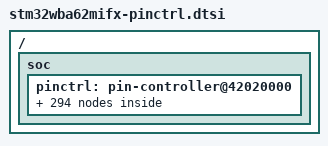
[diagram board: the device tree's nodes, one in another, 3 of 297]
/*
 * NOTE: Autogenerated file using genpinctrl.py
 *
 * SPDX-License-Identifier: Apache-2.0
 */

#include <zephyr/dt-bindings/pinctrl/stm32-pinctrl.h>

/ {
	soc {
		pinctrl: pin-controller@42020000 {

			/* ADC_IN / ADC_INN / ADC_INP */

			/omit-if-no-ref/ adc4_in9_pa0: adc4_in9_pa0 {
				pinmux = <STM32_PINMUX('A', 0, ANALOG)>;
			};

			/omit-if-no-ref/ adc4_in8_pa1: adc4_in8_pa1 {
				pinmux = <STM32_PINMUX('A', 1, ANALOG)>;
			};

			/omit-if-no-ref/ adc4_in7_pa2: adc4_in7_pa2 {
				pinmux = <STM32_PINMUX('A', 2, ANALOG)>;
			};

			/omit-if-no-ref/ adc4_in6_pa3: adc4_in6_pa3 {
				pinmux = <STM32_PINMUX('A', 3, ANALOG)>;
			};

			/omit-if-no-ref/ adc4_in5_pa4: adc4_in5_pa4 {
				pinmux = <STM32_PINMUX('A', 4, ANALOG)>;
			};

			/omit-if-no-ref/ adc4_in4_pa5: adc4_in4_pa5 {
				pinmux = <STM32_PINMUX('A', 5, ANALOG)>;
			};

			/omit-if-no-ref/ adc4_in3_pa6: adc4_in3_pa6 {
				pinmux = <STM32_PINMUX('A', 6, ANALOG)>;
			};

			/omit-if-no-ref/ adc4_in2_pa7: adc4_in2_pa7 {
				pinmux = <STM32_PINMUX('A', 7, ANALOG)>;
			};

			/omit-if-no-ref/ adc4_in1_pa8: adc4_in1_pa8 {
				pinmux = <STM32_PINMUX('A', 8, ANALOG)>;
			};

			/omit-if-no-ref/ adc4_in10_pb9: adc4_in10_pb9 {
				pinmux = <STM32_PINMUX('B', 9, ANALOG)>;
			};

			/* Analog */

			/omit-if-no-ref/ analog_pa0: analog_pa0 {
				pinmux = <STM32_PINMUX('A', 0, ANALOG)>;
			};

			/omit-if-no-ref/ analog_pa1: analog_pa1 {
				pinmux = <STM32_PINMUX('A', 1, ANALOG)>;
			};

			/omit-if-no-ref/ analog_pa2: analog_pa2 {
				pinmux = <STM32_PINMUX('A', 2, ANALOG)>;
			};

			/omit-if-no-ref/ analog_pa3: analog_pa3 {
				pinmux = <STM32_PINMUX('A', 3, ANALOG)>;
			};

			/omit-if-no-ref/ analog_pa4: analog_pa4 {
				pinmux = <STM32_PINMUX('A', 4, ANALOG)>;
			};

			/omit-if-no-ref/ analog_pa5: analog_pa5 {
				pinmux = <STM32_PINMUX('A', 5, ANALOG)>;
			};

			/omit-if-no-ref/ analog_pa6: analog_pa6 {
				pinmux = <STM32_PINMUX('A', 6, ANALOG)>;
			};

			/omit-if-no-ref/ analog_pa7: analog_pa7 {
				pinmux = <STM32_PINMUX('A', 7, ANALOG)>;
			};

			/omit-if-no-ref/ analog_pa8: analog_pa8 {
				pinmux = <STM32_PINMUX('A', 8, ANALOG)>;
			};

			/omit-if-no-ref/ analog_pa9: analog_pa9 {
				pinmux = <STM32_PINMUX('A', 9, ANALOG)>;
			};

			/omit-if-no-ref/ analog_pa10: analog_pa10 {
				pinmux = <STM32_PINMUX('A', 10, ANALOG)>;
			};

			/omit-if-no-ref/ analog_pa11: analog_pa11 {
				pinmux = <STM32_PINMUX('A', 11, ANALOG)>;
			};

			/omit-if-no-ref/ analog_pa12: analog_pa12 {
				pinmux = <STM32_PINMUX('A', 12, ANALOG)>;
			};

			/omit-if-no-ref/ analog_pa13: analog_pa13 {
				pinmux = <STM32_PINMUX('A', 13, ANALOG)>;
			};

			/omit-if-no-ref/ analog_pa14: analog_pa14 {
				pinmux = <STM32_PINMUX('A', 14, ANALOG)>;
			};

			/omit-if-no-ref/ analog_pa15: analog_pa15 {
				pinmux = <STM32_PINMUX('A', 15, ANALOG)>;
			};

			/omit-if-no-ref/ analog_pb0: analog_pb0 {
				pinmux = <STM32_PINMUX('B', 0, ANALOG)>;
			};

			/omit-if-no-ref/ analog_pb1: analog_pb1 {
				pinmux = <STM32_PINMUX('B', 1, ANALOG)>;
			};

			/omit-if-no-ref/ analog_pb2: analog_pb2 {
				pinmux = <STM32_PINMUX('B', 2, ANALOG)>;
			};

			/omit-if-no-ref/ analog_pb3: analog_pb3 {
				pinmux = <STM32_PINMUX('B', 3, ANALOG)>;
			};

			/omit-if-no-ref/ analog_pb4: analog_pb4 {
				pinmux = <STM32_PINMUX('B', 4, ANALOG)>;
			};

			/omit-if-no-ref/ analog_pb5: analog_pb5 {
				pinmux = <STM32_PINMUX('B', 5, ANALOG)>;
			};

			/omit-if-no-ref/ analog_pb6: analog_pb6 {
				pinmux = <STM32_PINMUX('B', 6, ANALOG)>;
			};

			/omit-if-no-ref/ analog_pb7: analog_pb7 {
				pinmux = <STM32_PINMUX('B', 7, ANALOG)>;
			};

			/omit-if-no-ref/ analog_pb8: analog_pb8 {
				pinmux = <STM32_PINMUX('B', 8, ANALOG)>;
			};

			/omit-if-no-ref/ analog_pb9: analog_pb9 {
				pinmux = <STM32_PINMUX('B', 9, ANALOG)>;
			};

			/omit-if-no-ref/ analog_pb10: analog_pb10 {
				pinmux = <STM32_PINMUX('B', 10, ANALOG)>;
			};

			/omit-if-no-ref/ analog_pb11: analog_pb11 {
				pinmux = <STM32_PINMUX('B', 11, ANALOG)>;
			};

			/omit-if-no-ref/ analog_pb12: analog_pb12 {
				pinmux = <STM32_PINMUX('B', 12, ANALOG)>;
			};

			/omit-if-no-ref/ analog_pb13: analog_pb13 {
				pinmux = <STM32_PINMUX('B', 13, ANALOG)>;
			};

			/omit-if-no-ref/ analog_pb14: analog_pb14 {
				pinmux = <STM32_PINMUX('B', 14, ANALOG)>;
			};

			/omit-if-no-ref/ analog_pb15: analog_pb15 {
				pinmux = <STM32_PINMUX('B', 15, ANALOG)>;
			};

			/omit-if-no-ref/ analog_pc0: analog_pc0 {
				pinmux = <STM32_PINMUX('C', 0, ANALOG)>;
			};

			/omit-if-no-ref/ analog_pc1: analog_pc1 {
				pinmux = <STM32_PINMUX('C', 1, ANALOG)>;
			};

			/omit-if-no-ref/ analog_pc3: analog_pc3 {
				pinmux = <STM32_PINMUX('C', 3, ANALOG)>;
			};

			/omit-if-no-ref/ analog_pc4: analog_pc4 {
				pinmux = <STM32_PINMUX('C', 4, ANALOG)>;
			};

			/omit-if-no-ref/ analog_pc5: analog_pc5 {
				pinmux = <STM32_PINMUX('C', 5, ANALOG)>;
			};

			/omit-if-no-ref/ analog_pc6: analog_pc6 {
				pinmux = <STM32_PINMUX('C', 6, ANALOG)>;
			};

			/omit-if-no-ref/ analog_pc7: analog_pc7 {
				pinmux = <STM32_PINMUX('C', 7, ANALOG)>;
			};

			/omit-if-no-ref/ analog_pc8: analog_pc8 {
				pinmux = <STM32_PINMUX('C', 8, ANALOG)>;
			};

			/omit-if-no-ref/ analog_pc13: analog_pc13 {
				pinmux = <STM32_PINMUX('C', 13, ANALOG)>;
			};

			/omit-if-no-ref/ analog_pc14: analog_pc14 {
				pinmux = <STM32_PINMUX('C', 14, ANALOG)>;
			};

			/omit-if-no-ref/ analog_pc15: analog_pc15 {
				pinmux = <STM32_PINMUX('C', 15, ANALOG)>;
			};

			/omit-if-no-ref/ analog_pd5: analog_pd5 {
				pinmux = <STM32_PINMUX('D', 5, ANALOG)>;
			};

			/omit-if-no-ref/ analog_pd6: analog_pd6 {
				pinmux = <STM32_PINMUX('D', 6, ANALOG)>;
			};

			/omit-if-no-ref/ analog_pd7: analog_pd7 {
				pinmux = <STM32_PINMUX('D', 7, ANALOG)>;
			};

			/omit-if-no-ref/ analog_pd8: analog_pd8 {
				pinmux = <STM32_PINMUX('D', 8, ANALOG)>;
			};

			/omit-if-no-ref/ analog_pd9: analog_pd9 {
				pinmux = <STM32_PINMUX('D', 9, ANALOG)>;
			};

			/omit-if-no-ref/ analog_pd14: analog_pd14 {
				pinmux = <STM32_PINMUX('D', 14, ANALOG)>;
			};

			/omit-if-no-ref/ analog_pe0: analog_pe0 {
				pinmux = <STM32_PINMUX('E', 0, ANALOG)>;
			};

			/omit-if-no-ref/ analog_pe1: analog_pe1 {
				pinmux = <STM32_PINMUX('E', 1, ANALOG)>;
			};

			/omit-if-no-ref/ analog_pe2: analog_pe2 {
				pinmux = <STM32_PINMUX('E', 2, ANALOG)>;
			};

			/omit-if-no-ref/ analog_pe3: analog_pe3 {
				pinmux = <STM32_PINMUX('E', 3, ANALOG)>;
			};

			/omit-if-no-ref/ analog_ph3: analog_ph3 {
				pinmux = <STM32_PINMUX('H', 3, ANALOG)>;
			};

			/* COMP_IN */

			/omit-if-no-ref/ comp1_inm_pa1: comp1_inm_pa1 {
				pinmux = <STM32_PINMUX('A', 1, ANALOG)>;
			};

			/omit-if-no-ref/ comp1_inp_pa2: comp1_inp_pa2 {
				pinmux = <STM32_PINMUX('A', 2, ANALOG)>;
			};

			/omit-if-no-ref/ comp2_inp_pa0: comp2_inp_pa0 {
				pinmux = <STM32_PINMUX('A', 0, ANALOG)>;
			};

			/omit-if-no-ref/ comp2_inm_pb9: comp2_inm_pb9 {
				pinmux = <STM32_PINMUX('B', 9, ANALOG)>;
			};

			/* COMP_OUT */

			/omit-if-no-ref/ comp1_out_pa7: comp1_out_pa7 {
				pinmux = <STM32_PINMUX('A', 7, AF12)>;
			};

			/omit-if-no-ref/ comp1_out_pb8: comp1_out_pb8 {
				pinmux = <STM32_PINMUX('B', 8, AF12)>;
			};

			/omit-if-no-ref/ comp2_out_pa12: comp2_out_pa12 {
				pinmux = <STM32_PINMUX('A', 12, AF12)>;
			};

			/omit-if-no-ref/ comp2_out_pa14: comp2_out_pa14 {
				pinmux = <STM32_PINMUX('A', 14, AF12)>;
			};

			/* I2C_SCL */

			/omit-if-no-ref/ i2c1_scl_pa15: i2c1_scl_pa15 {
				pinmux = <STM32_PINMUX('A', 15, AF4)>;
				bias-pull-up;
				drive-open-drain;
			};

			/omit-if-no-ref/ i2c1_scl_pb2: i2c1_scl_pb2 {
				pinmux = <STM32_PINMUX('B', 2, AF4)>;
				bias-pull-up;
				drive-open-drain;
			};

			/omit-if-no-ref/ i2c2_scl_pb10: i2c2_scl_pb10 {
				pinmux = <STM32_PINMUX('B', 10, AF4)>;
				bias-pull-up;
				drive-open-drain;
			};

			/omit-if-no-ref/ i2c2_scl_pb13: i2c2_scl_pb13 {
				pinmux = <STM32_PINMUX('B', 13, AF4)>;
				bias-pull-up;
				drive-open-drain;
			};

			/omit-if-no-ref/ i2c3_scl_pa6: i2c3_scl_pa6 {
				pinmux = <STM32_PINMUX('A', 6, AF4)>;
				bias-pull-up;
				drive-open-drain;
			};

			/omit-if-no-ref/ i2c3_scl_pb2: i2c3_scl_pb2 {
				pinmux = <STM32_PINMUX('B', 2, AF6)>;
				bias-pull-up;
				drive-open-drain;
			};

			/omit-if-no-ref/ i2c3_scl_pc0: i2c3_scl_pc0 {
				pinmux = <STM32_PINMUX('C', 0, AF4)>;
				bias-pull-up;
				drive-open-drain;
			};

			/omit-if-no-ref/ i2c4_scl_pb10: i2c4_scl_pb10 {
				pinmux = <STM32_PINMUX('B', 10, AF3)>;
				bias-pull-up;
				drive-open-drain;
			};

			/* I2C_SDA */

			/omit-if-no-ref/ i2c1_sda_pb1: i2c1_sda_pb1 {
				pinmux = <STM32_PINMUX('B', 1, AF4)>;
				bias-pull-up;
				drive-open-drain;
			};

			/omit-if-no-ref/ i2c1_sda_pb3: i2c1_sda_pb3 {
				pinmux = <STM32_PINMUX('B', 3, AF4)>;
				bias-pull-up;
				drive-open-drain;
			};

			/omit-if-no-ref/ i2c2_sda_pb11: i2c2_sda_pb11 {
				pinmux = <STM32_PINMUX('B', 11, AF4)>;
				bias-pull-up;
				drive-open-drain;
			};

			/omit-if-no-ref/ i2c2_sda_pb14: i2c2_sda_pb14 {
				pinmux = <STM32_PINMUX('B', 14, AF4)>;
				bias-pull-up;
				drive-open-drain;
			};

			/omit-if-no-ref/ i2c3_sda_pa7: i2c3_sda_pa7 {
				pinmux = <STM32_PINMUX('A', 7, AF4)>;
				bias-pull-up;
				drive-open-drain;
			};

			/omit-if-no-ref/ i2c3_sda_pb1: i2c3_sda_pb1 {
				pinmux = <STM32_PINMUX('B', 1, AF6)>;
				bias-pull-up;
				drive-open-drain;
			};

			/omit-if-no-ref/ i2c3_sda_pc1: i2c3_sda_pc1 {
				pinmux = <STM32_PINMUX('C', 1, AF4)>;
				bias-pull-up;
				drive-open-drain;
			};

			/omit-if-no-ref/ i2c4_sda_pb11: i2c4_sda_pb11 {
				pinmux = <STM32_PINMUX('B', 11, AF3)>;
				bias-pull-up;
				drive-open-drain;
			};

			/* I2C_SMBA */

			/omit-if-no-ref/ i2c1_smba_pb15: i2c1_smba_pb15 {
				pinmux = <STM32_PINMUX('B', 15, AF4)>;
				bias-pull-up;
			};

			/omit-if-no-ref/ i2c2_smba_pb12: i2c2_smba_pb12 {
				pinmux = <STM32_PINMUX('B', 12, AF4)>;
				bias-pull-up;
			};

			/omit-if-no-ref/ i2c3_smba_pb15: i2c3_smba_pb15 {
				pinmux = <STM32_PINMUX('B', 15, AF6)>;
				bias-pull-up;
			};

			/omit-if-no-ref/ i2c4_smba_pa14: i2c4_smba_pa14 {
				pinmux = <STM32_PINMUX('A', 14, AF5)>;
				bias-pull-up;
			};

			/* JTAG PORT */

			/omit-if-no-ref/ debug_jtms_swdio_pa13: debug_jtms_swdio_pa13 {
				pinmux = <STM32_PINMUX('A', 13, AF0)>;
			};

			/omit-if-no-ref/ debug_jtck_swclk_pa14: debug_jtck_swclk_pa14 {
				pinmux = <STM32_PINMUX('A', 14, AF0)>;
			};

			/omit-if-no-ref/ debug_jtdi_pa15: debug_jtdi_pa15 {
				pinmux = <STM32_PINMUX('A', 15, AF0)>;
			};

			/omit-if-no-ref/ debug_jtdo_swo_pb3: debug_jtdo_swo_pb3 {
				pinmux = <STM32_PINMUX('B', 3, AF0)>;
			};

			/omit-if-no-ref/ debug_njtrst_pb4: debug_njtrst_pb4 {
				pinmux = <STM32_PINMUX('B', 4, AF0)>;
			};

			/* RCC_MCO */

			/omit-if-no-ref/ rcc_mco_pa8: rcc_mco_pa8 {
				pinmux = <STM32_PINMUX('A', 8, AF0)>;
				slew-rate = "very-high-speed";
			};

			/* SAI */

			/omit-if-no-ref/ sai1_ck1_pa1: sai1_ck1_pa1 {
				pinmux = <STM32_PINMUX('A', 1, AF3)>;
			};

			/omit-if-no-ref/ sai1_d1_pa2: sai1_d1_pa2 {
				pinmux = <STM32_PINMUX('A', 2, AF3)>;
			};

			/omit-if-no-ref/ sai1_d2_pa5: sai1_d2_pa5 {
				pinmux = <STM32_PINMUX('A', 5, AF3)>;
			};

			/omit-if-no-ref/ sai1_ck2_pa6: sai1_ck2_pa6 {
				pinmux = <STM32_PINMUX('A', 6, AF3)>;
			};

			/omit-if-no-ref/ sai1_mclk_a_pa6: sai1_mclk_a_pa6 {
				pinmux = <STM32_PINMUX('A', 6, AF13)>;
			};

			/omit-if-no-ref/ sai1_sck_a_pa7: sai1_sck_a_pa7 {
				pinmux = <STM32_PINMUX('A', 7, AF13)>;
			};

			/omit-if-no-ref/ sai1_fs_a_pa8: sai1_fs_a_pa8 {
				pinmux = <STM32_PINMUX('A', 8, AF13)>;
			};

			/omit-if-no-ref/ sai1_ck1_pa9: sai1_ck1_pa9 {
				pinmux = <STM32_PINMUX('A', 9, AF3)>;
			};

			/omit-if-no-ref/ sai1_d1_pa10: sai1_d1_pa10 {
				pinmux = <STM32_PINMUX('A', 10, AF3)>;
			};

			/omit-if-no-ref/ sai1_mclk_b_pb4: sai1_mclk_b_pb4 {
				pinmux = <STM32_PINMUX('B', 4, AF13)>;
			};

			/omit-if-no-ref/ sai1_d2_pb5: sai1_d2_pb5 {
				pinmux = <STM32_PINMUX('B', 5, AF3)>;
			};

			/omit-if-no-ref/ sai1_fs_b_pb5: sai1_fs_b_pb5 {
				pinmux = <STM32_PINMUX('B', 5, AF13)>;
			};

			/omit-if-no-ref/ sai1_sck_b_pb6: sai1_sck_b_pb6 {
				pinmux = <STM32_PINMUX('B', 6, AF13)>;
			};

			/omit-if-no-ref/ sai1_sd_b_pb7: sai1_sd_b_pb7 {
				pinmux = <STM32_PINMUX('B', 7, AF13)>;
			};

			/omit-if-no-ref/ sai1_sd_a_pb12: sai1_sd_a_pb12 {
				pinmux = <STM32_PINMUX('B', 12, AF13)>;
			};

			/omit-if-no-ref/ sai1_sd_a_pb14: sai1_sd_a_pb14 {
				pinmux = <STM32_PINMUX('B', 14, AF13)>;
			};

			/omit-if-no-ref/ sai1_sd_a_pc1: sai1_sd_a_pc1 {
				pinmux = <STM32_PINMUX('C', 1, AF13)>;
			};

			/omit-if-no-ref/ sai1_d1_pc3: sai1_d1_pc3 {
				pinmux = <STM32_PINMUX('C', 3, AF3)>;
			};

			/omit-if-no-ref/ sai1_sd_a_pc3: sai1_sd_a_pc3 {
				pinmux = <STM32_PINMUX('C', 3, AF13)>;
			};

			/omit-if-no-ref/ sai1_d2_pc4: sai1_d2_pc4 {
				pinmux = <STM32_PINMUX('C', 4, AF3)>;
			};

			/omit-if-no-ref/ sai1_fs_a_pc4: sai1_fs_a_pc4 {
				pinmux = <STM32_PINMUX('C', 4, AF13)>;
			};

			/omit-if-no-ref/ sai1_d3_pc5: sai1_d3_pc5 {
				pinmux = <STM32_PINMUX('C', 5, AF3)>;
			};

			/omit-if-no-ref/ sai1_sd_b_pc5: sai1_sd_b_pc5 {
				pinmux = <STM32_PINMUX('C', 5, AF13)>;
			};

			/omit-if-no-ref/ sai1_d1_pd5: sai1_d1_pd5 {
				pinmux = <STM32_PINMUX('D', 5, AF3)>;
			};

			/omit-if-no-ref/ sai1_sd_a_pd5: sai1_sd_a_pd5 {
				pinmux = <STM32_PINMUX('D', 5, AF13)>;
			};

			/omit-if-no-ref/ sai1_ck1_pe2: sai1_ck1_pe2 {
				pinmux = <STM32_PINMUX('E', 2, AF3)>;
			};

			/omit-if-no-ref/ sai1_mclk_a_pe2: sai1_mclk_a_pe2 {
				pinmux = <STM32_PINMUX('E', 2, AF13)>;
			};

			/omit-if-no-ref/ sai1_sd_b_pe3: sai1_sd_b_pe3 {
				pinmux = <STM32_PINMUX('E', 3, AF13)>;
			};

			/* SPI_MISO */

			/omit-if-no-ref/ spi1_miso_pb3: spi1_miso_pb3 {
				pinmux = <STM32_PINMUX('B', 3, AF5)>;
				bias-pull-down;
			};

			/omit-if-no-ref/ spi2_miso_pa9: spi2_miso_pa9 {
				pinmux = <STM32_PINMUX('A', 9, AF5)>;
				bias-pull-down;
			};

			/omit-if-no-ref/ spi2_miso_pb14: spi2_miso_pb14 {
				pinmux = <STM32_PINMUX('B', 14, AF5)>;
				bias-pull-down;
			};

			/omit-if-no-ref/ spi3_miso_pa1: spi3_miso_pa1 {
				pinmux = <STM32_PINMUX('A', 1, AF6)>;
				bias-pull-down;
			};

			/omit-if-no-ref/ spi3_miso_pb9: spi3_miso_pb9 {
				pinmux = <STM32_PINMUX('B', 9, AF6)>;
				bias-pull-down;
			};

			/omit-if-no-ref/ spi3_miso_pc4: spi3_miso_pc4 {
				pinmux = <STM32_PINMUX('C', 4, AF6)>;
				bias-pull-down;
			};

			/* SPI_MOSI */

			/omit-if-no-ref/ spi1_mosi_pa15: spi1_mosi_pa15 {
				pinmux = <STM32_PINMUX('A', 15, AF5)>;
				bias-pull-down;
			};

			/omit-if-no-ref/ spi2_mosi_pb0: spi2_mosi_pb0 {
				pinmux = <STM32_PINMUX('B', 0, AF5)>;
				bias-pull-down;
			};

			/omit-if-no-ref/ spi2_mosi_pc1: spi2_mosi_pc1 {
				pinmux = <STM32_PINMUX('C', 1, AF3)>;
				bias-pull-down;
			};

			/omit-if-no-ref/ spi2_mosi_pc3: spi2_mosi_pc3 {
				pinmux = <STM32_PINMUX('C', 3, AF5)>;
				bias-pull-down;
			};

			/omit-if-no-ref/ spi3_mosi_pb8: spi3_mosi_pb8 {
				pinmux = <STM32_PINMUX('B', 8, AF6)>;
				bias-pull-down;
			};

			/omit-if-no-ref/ spi3_mosi_pc3: spi3_mosi_pc3 {
				pinmux = <STM32_PINMUX('C', 3, AF6)>;
				bias-pull-down;
			};

			/omit-if-no-ref/ spi3_mosi_pd5: spi3_mosi_pd5 {
				pinmux = <STM32_PINMUX('D', 5, AF5)>;
				bias-pull-down;
			};

			/* SPI_NSS */

			/omit-if-no-ref/ spi1_nss_pa12: spi1_nss_pa12 {
				pinmux = <STM32_PINMUX('A', 12, AF5)>;
				bias-pull-up;
			};

			/omit-if-no-ref/ spi2_nss_pa10: spi2_nss_pa10 {
				pinmux = <STM32_PINMUX('A', 10, AF6)>;
				bias-pull-up;
			};

			/omit-if-no-ref/ spi2_nss_pb9: spi2_nss_pb9 {
				pinmux = <STM32_PINMUX('B', 9, AF5)>;
				bias-pull-up;
			};

			/omit-if-no-ref/ spi2_nss_pb12: spi2_nss_pb12 {
				pinmux = <STM32_PINMUX('B', 12, AF6)>;
				bias-pull-up;
			};

			/omit-if-no-ref/ spi3_nss_pa5: spi3_nss_pa5 {
				pinmux = <STM32_PINMUX('A', 5, AF6)>;
				bias-pull-up;
			};

			/* SPI_SCK */

			/omit-if-no-ref/ spi1_sck_pb4: spi1_sck_pb4 {
				pinmux = <STM32_PINMUX('B', 4, AF5)>;
				bias-pull-down;
				slew-rate = "very-high-speed";
			};

			/omit-if-no-ref/ spi2_sck_pa9: spi2_sck_pa9 {
				pinmux = <STM32_PINMUX('A', 9, AF6)>;
				bias-pull-down;
				slew-rate = "very-high-speed";
			};

			/omit-if-no-ref/ spi2_sck_pb10: spi2_sck_pb10 {
				pinmux = <STM32_PINMUX('B', 10, AF5)>;
				bias-pull-down;
				slew-rate = "very-high-speed";
			};

			/omit-if-no-ref/ spi2_sck_pb13: spi2_sck_pb13 {
				pinmux = <STM32_PINMUX('B', 13, AF5)>;
				bias-pull-down;
				slew-rate = "very-high-speed";
			};

			/omit-if-no-ref/ spi3_sck_pa0: spi3_sck_pa0 {
				pinmux = <STM32_PINMUX('A', 0, AF6)>;
				bias-pull-down;
				slew-rate = "very-high-speed";
			};

			/omit-if-no-ref/ spi3_sck_pa7: spi3_sck_pa7 {
				pinmux = <STM32_PINMUX('A', 7, AF6)>;
				bias-pull-down;
				slew-rate = "very-high-speed";
			};

			/* TIM_BKIN */

			/omit-if-no-ref/ tim1_bkin_pa2: tim1_bkin_pa2 {
				pinmux = <STM32_PINMUX('A', 2, AF1)>;
			};

			/omit-if-no-ref/ tim1_bkin2_pb15: tim1_bkin2_pb15 {
				pinmux = <STM32_PINMUX('B', 15, AF1)>;
			};

			/omit-if-no-ref/ tim1_bkin2_pc13: tim1_bkin2_pc13 {
				pinmux = <STM32_PINMUX('C', 13, AF2)>;
			};

			/omit-if-no-ref/ tim16_bkin_pb10: tim16_bkin_pb10 {
				pinmux = <STM32_PINMUX('B', 10, AF14)>;
			};

			/omit-if-no-ref/ tim16_bkin_pb15: tim16_bkin_pb15 {
				pinmux = <STM32_PINMUX('B', 15, AF14)>;
			};

			/omit-if-no-ref/ tim17_bkin_pa15: tim17_bkin_pa15 {
				pinmux = <STM32_PINMUX('A', 15, AF14)>;
			};

			/* TIM_CH / TIM_CHN */

			/omit-if-no-ref/ tim1_ch2n_pa0: tim1_ch2n_pa0 {
				pinmux = <STM32_PINMUX('A', 0, AF1)>;
			};

			/omit-if-no-ref/ tim1_ch1n_pa1: tim1_ch1n_pa1 {
				pinmux = <STM32_PINMUX('A', 1, AF1)>;
			};

			/omit-if-no-ref/ tim1_ch1_pa11: tim1_ch1_pa11 {
				pinmux = <STM32_PINMUX('A', 11, AF1)>;
			};

			/omit-if-no-ref/ tim1_ch2_pa12: tim1_ch2_pa12 {
				pinmux = <STM32_PINMUX('A', 12, AF1)>;
			};

			/omit-if-no-ref/ tim1_ch3n_pb0: tim1_ch3n_pb0 {
				pinmux = <STM32_PINMUX('B', 0, AF1)>;
			};

			/omit-if-no-ref/ tim1_ch2n_pb1: tim1_ch2n_pb1 {
				pinmux = <STM32_PINMUX('B', 1, AF1)>;
			};

			/omit-if-no-ref/ tim1_ch1n_pb2: tim1_ch1n_pb2 {
				pinmux = <STM32_PINMUX('B', 2, AF1)>;
			};

			/omit-if-no-ref/ tim1_ch4_pb3: tim1_ch4_pb3 {
				pinmux = <STM32_PINMUX('B', 3, AF1)>;
			};

			/omit-if-no-ref/ tim1_ch3_pb4: tim1_ch3_pb4 {
				pinmux = <STM32_PINMUX('B', 4, AF1)>;
			};

			/omit-if-no-ref/ tim1_ch4n_pb7: tim1_ch4n_pb7 {
				pinmux = <STM32_PINMUX('B', 7, AF1)>;
			};

			/omit-if-no-ref/ tim1_ch1_pb8: tim1_ch1_pb8 {
				pinmux = <STM32_PINMUX('B', 8, AF1)>;
			};

			/omit-if-no-ref/ tim1_ch3n_pb9: tim1_ch3n_pb9 {
				pinmux = <STM32_PINMUX('B', 9, AF1)>;
			};

			/omit-if-no-ref/ tim1_ch4n_pc5: tim1_ch4n_pc5 {
				pinmux = <STM32_PINMUX('C', 5, AF1)>;
			};

			/omit-if-no-ref/ tim2_ch1_pa5: tim2_ch1_pa5 {
				pinmux = <STM32_PINMUX('A', 5, AF1)>;
			};

			/omit-if-no-ref/ tim2_ch4_pa6: tim2_ch4_pa6 {
				pinmux = <STM32_PINMUX('A', 6, AF1)>;
			};

			/omit-if-no-ref/ tim2_ch3_pa7: tim2_ch3_pa7 {
				pinmux = <STM32_PINMUX('A', 7, AF1)>;
			};

			/omit-if-no-ref/ tim2_ch2_pa8: tim2_ch2_pa8 {
				pinmux = <STM32_PINMUX('A', 8, AF1)>;
			};

			/omit-if-no-ref/ tim2_ch1_pb6: tim2_ch1_pb6 {
				pinmux = <STM32_PINMUX('B', 6, AF1)>;
			};

			/omit-if-no-ref/ tim2_ch1_pb12: tim2_ch1_pb12 {
				pinmux = <STM32_PINMUX('B', 12, AF1)>;
			};

			/omit-if-no-ref/ tim3_ch3_pa0: tim3_ch3_pa0 {
				pinmux = <STM32_PINMUX('A', 0, AF2)>;
			};

			/omit-if-no-ref/ tim3_ch2_pa1: tim3_ch2_pa1 {
				pinmux = <STM32_PINMUX('A', 1, AF2)>;
			};

			/omit-if-no-ref/ tim3_ch1_pa2: tim3_ch1_pa2 {
				pinmux = <STM32_PINMUX('A', 2, AF2)>;
			};

			/omit-if-no-ref/ tim3_ch2_pa9: tim3_ch2_pa9 {
				pinmux = <STM32_PINMUX('A', 9, AF2)>;
			};

			/omit-if-no-ref/ tim3_ch1_pa10: tim3_ch1_pa10 {
				pinmux = <STM32_PINMUX('A', 10, AF2)>;
			};

			/omit-if-no-ref/ tim3_ch1_pb5: tim3_ch1_pb5 {
				pinmux = <STM32_PINMUX('B', 5, AF2)>;
			};

			/omit-if-no-ref/ tim3_ch4_pb9: tim3_ch4_pb9 {
				pinmux = <STM32_PINMUX('B', 9, AF2)>;
			};

			/omit-if-no-ref/ tim3_ch4_pb13: tim3_ch4_pb13 {
				pinmux = <STM32_PINMUX('B', 13, AF2)>;
			};

			/omit-if-no-ref/ tim3_ch3_pb14: tim3_ch3_pb14 {
				pinmux = <STM32_PINMUX('B', 14, AF2)>;
			};

			/omit-if-no-ref/ tim3_ch1_pc3: tim3_ch1_pc3 {
				pinmux = <STM32_PINMUX('C', 3, AF2)>;
			};

			/omit-if-no-ref/ tim3_ch2_pc4: tim3_ch2_pc4 {
				pinmux = <STM32_PINMUX('C', 4, AF2)>;
			};

			/omit-if-no-ref/ tim3_ch1_pc6: tim3_ch1_pc6 {
				pinmux = <STM32_PINMUX('C', 6, AF2)>;
			};

			/omit-if-no-ref/ tim3_ch2_pc7: tim3_ch2_pc7 {
				pinmux = <STM32_PINMUX('C', 7, AF2)>;
			};

			/omit-if-no-ref/ tim3_ch3_pc8: tim3_ch3_pc8 {
				pinmux = <STM32_PINMUX('C', 8, AF2)>;
			};

			/omit-if-no-ref/ tim3_ch1_pe3: tim3_ch1_pe3 {
				pinmux = <STM32_PINMUX('E', 3, AF2)>;
			};

			/omit-if-no-ref/ tim4_ch1_pb6: tim4_ch1_pb6 {
				pinmux = <STM32_PINMUX('B', 6, AF12)>;
			};

			/omit-if-no-ref/ tim4_ch2_pb7: tim4_ch2_pb7 {
				pinmux = <STM32_PINMUX('B', 7, AF12)>;
			};

			/omit-if-no-ref/ tim4_ch3_pb8: tim4_ch3_pb8 {
				pinmux = <STM32_PINMUX('B', 8, AF13)>;
			};

			/omit-if-no-ref/ tim4_ch4_pb9: tim4_ch4_pb9 {
				pinmux = <STM32_PINMUX('B', 9, AF12)>;
			};

			/omit-if-no-ref/ tim4_ch3_pd14: tim4_ch3_pd14 {
				pinmux = <STM32_PINMUX('D', 14, AF13)>;
			};

			/omit-if-no-ref/ tim16_ch1_pa2: tim16_ch1_pa2 {
				pinmux = <STM32_PINMUX('A', 2, AF14)>;
			};

			/omit-if-no-ref/ tim16_ch1n_pa3: tim16_ch1n_pa3 {
				pinmux = <STM32_PINMUX('A', 3, AF14)>;
			};

			/omit-if-no-ref/ tim16_ch1_pa4: tim16_ch1_pa4 {
				pinmux = <STM32_PINMUX('A', 4, AF14)>;
			};

			/omit-if-no-ref/ tim16_ch1n_pb8: tim16_ch1n_pb8 {
				pinmux = <STM32_PINMUX('B', 8, AF14)>;
			};

			/omit-if-no-ref/ tim16_ch1_pb9: tim16_ch1_pb9 {
				pinmux = <STM32_PINMUX('B', 9, AF14)>;
			};

			/omit-if-no-ref/ tim16_ch1_pe0: tim16_ch1_pe0 {
				pinmux = <STM32_PINMUX('E', 0, AF14)>;
			};

			/omit-if-no-ref/ tim17_ch1_pa1: tim17_ch1_pa1 {
				pinmux = <STM32_PINMUX('A', 1, AF14)>;
			};

			/omit-if-no-ref/ tim17_ch1n_pb3: tim17_ch1n_pb3 {
				pinmux = <STM32_PINMUX('B', 3, AF14)>;
			};

			/omit-if-no-ref/ tim17_ch1_pb4: tim17_ch1_pb4 {
				pinmux = <STM32_PINMUX('B', 4, AF14)>;
			};

			/omit-if-no-ref/ tim17_ch1_pe1: tim17_ch1_pe1 {
				pinmux = <STM32_PINMUX('E', 1, AF14)>;
			};

			/* TSC */

			/omit-if-no-ref/ tsc_g2_io2_pa0: tsc_g2_io2_pa0 {
				pinmux = <STM32_PINMUX('A', 0, AF9)>;
			};

			/omit-if-no-ref/ tsc_g2_io1_pa1: tsc_g2_io1_pa1 {
				pinmux = <STM32_PINMUX('A', 1, AF9)>;
			};

			/omit-if-no-ref/ tsc_g4_io4_pa2: tsc_g4_io4_pa2 {
				pinmux = <STM32_PINMUX('A', 2, AF9)>;
			};

			/omit-if-no-ref/ tsc_g4_io2_pa3: tsc_g4_io2_pa3 {
				pinmux = <STM32_PINMUX('A', 3, AF9)>;
			};

			/omit-if-no-ref/ tsc_g4_io1_pa4: tsc_g4_io1_pa4 {
				pinmux = <STM32_PINMUX('A', 4, AF9)>;
			};

			/omit-if-no-ref/ tsc_g1_io4_pa5: tsc_g1_io4_pa5 {
				pinmux = <STM32_PINMUX('A', 5, AF9)>;
			};

			/omit-if-no-ref/ tsc_g1_io3_pa6: tsc_g1_io3_pa6 {
				pinmux = <STM32_PINMUX('A', 6, AF9)>;
			};

			/omit-if-no-ref/ tsc_g1_io2_pa7: tsc_g1_io2_pa7 {
				pinmux = <STM32_PINMUX('A', 7, AF9)>;
			};

			/omit-if-no-ref/ tsc_g1_io1_pa8: tsc_g1_io1_pa8 {
				pinmux = <STM32_PINMUX('A', 8, AF9)>;
			};

			/omit-if-no-ref/ tsc_g3_io4_pa12: tsc_g3_io4_pa12 {
				pinmux = <STM32_PINMUX('A', 12, AF9)>;
			};

			/omit-if-no-ref/ tsc_g3_io3_pa15: tsc_g3_io3_pa15 {
				pinmux = <STM32_PINMUX('A', 15, AF9)>;
			};

			/omit-if-no-ref/ tsc_g3_io2_pb3: tsc_g3_io2_pb3 {
				pinmux = <STM32_PINMUX('B', 3, AF9)>;
			};

			/omit-if-no-ref/ tsc_g3_io1_pb4: tsc_g3_io1_pb4 {
				pinmux = <STM32_PINMUX('B', 4, AF9)>;
			};

			/omit-if-no-ref/ tsc_g5_io4_pb5: tsc_g5_io4_pb5 {
				pinmux = <STM32_PINMUX('B', 5, AF9)>;
			};

			/omit-if-no-ref/ tsc_g5_io3_pb6: tsc_g5_io3_pb6 {
				pinmux = <STM32_PINMUX('B', 6, AF9)>;
			};

			/omit-if-no-ref/ tsc_g5_io2_pb7: tsc_g5_io2_pb7 {
				pinmux = <STM32_PINMUX('B', 7, AF9)>;
			};

			/omit-if-no-ref/ tsc_g2_io4_pb8: tsc_g2_io4_pb8 {
				pinmux = <STM32_PINMUX('B', 8, AF9)>;
			};

			/omit-if-no-ref/ tsc_g2_io3_pb9: tsc_g2_io3_pb9 {
				pinmux = <STM32_PINMUX('B', 9, AF9)>;
			};

			/omit-if-no-ref/ tsc_g4_io3_pb10: tsc_g4_io3_pb10 {
				pinmux = <STM32_PINMUX('B', 10, AF9)>;
			};

			/omit-if-no-ref/ tsc_sync_pb12: tsc_sync_pb12 {
				pinmux = <STM32_PINMUX('B', 12, AF9)>;
			};

			/omit-if-no-ref/ tsc_g6_io2_pb13: tsc_g6_io2_pb13 {
				pinmux = <STM32_PINMUX('B', 13, AF9)>;
			};

			/omit-if-no-ref/ tsc_g6_io1_pb14: tsc_g6_io1_pb14 {
				pinmux = <STM32_PINMUX('B', 14, AF9)>;
			};

			/omit-if-no-ref/ tsc_g5_io1_pc13: tsc_g5_io1_pc13 {
				pinmux = <STM32_PINMUX('C', 13, AF9)>;
			};

			/omit-if-no-ref/ tsc_g7_io4_pe0: tsc_g7_io4_pe0 {
				pinmux = <STM32_PINMUX('E', 0, AF9)>;
			};

			/omit-if-no-ref/ tsc_g7_io3_pe1: tsc_g7_io3_pe1 {
				pinmux = <STM32_PINMUX('E', 1, AF9)>;
			};

			/omit-if-no-ref/ tsc_g7_io2_pe2: tsc_g7_io2_pe2 {
				pinmux = <STM32_PINMUX('E', 2, AF9)>;
			};

			/omit-if-no-ref/ tsc_g7_io1_pe3: tsc_g7_io1_pe3 {
				pinmux = <STM32_PINMUX('E', 3, AF9)>;
			};

			/* UART_CTS / USART_CTS / LPUART_CTS */

			/omit-if-no-ref/ lpuart1_cts_pa0: lpuart1_cts_pa0 {
				pinmux = <STM32_PINMUX('A', 0, AF8)>;
				bias-pull-up;
			};

			/omit-if-no-ref/ usart1_cts_pa4: usart1_cts_pa4 {
				pinmux = <STM32_PINMUX('A', 4, AF7)>;
				bias-pull-up;
			};

			/omit-if-no-ref/ usart1_cts_pa7: usart1_cts_pa7 {
				pinmux = <STM32_PINMUX('A', 7, AF7)>;
				bias-pull-up;
			};

			/omit-if-no-ref/ lpuart1_cts_pb15: lpuart1_cts_pb15 {
				pinmux = <STM32_PINMUX('B', 15, AF8)>;
				bias-pull-up;
			};

			/omit-if-no-ref/ usart2_cts_pb2: usart2_cts_pb2 {
				pinmux = <STM32_PINMUX('B', 2, AF3)>;
				bias-pull-up;
			};

			/omit-if-no-ref/ usart2_cts_pb15: usart2_cts_pb15 {
				pinmux = <STM32_PINMUX('B', 15, AF3)>;
				bias-pull-up;
			};

			/omit-if-no-ref/ usart3_cts_pa6: usart3_cts_pa6 {
				pinmux = <STM32_PINMUX('A', 6, AF8)>;
				bias-pull-up;
			};

			/omit-if-no-ref/ usart3_cts_pb13: usart3_cts_pb13 {
				pinmux = <STM32_PINMUX('B', 13, AF7)>;
				bias-pull-up;
			};

			/* UART_DE / USART_DE / LPUART_DE */

			/omit-if-no-ref/ usart1_de_pa2: usart1_de_pa2 {
				pinmux = <STM32_PINMUX('A', 2, AF7)>;
				drive-push-pull;
			};

			/omit-if-no-ref/ usart1_de_pa3: usart1_de_pa3 {
				pinmux = <STM32_PINMUX('A', 3, AF7)>;
				drive-push-pull;
			};

			/omit-if-no-ref/ usart1_de_pa6: usart1_de_pa6 {
				pinmux = <STM32_PINMUX('A', 6, AF7)>;
				drive-push-pull;
			};

			/omit-if-no-ref/ lpuart1_de_pa9: lpuart1_de_pa9 {
				pinmux = <STM32_PINMUX('A', 9, AF8)>;
				drive-push-pull;
			};

			/omit-if-no-ref/ lpuart1_de_pb9: lpuart1_de_pb9 {
				pinmux = <STM32_PINMUX('B', 9, AF8)>;
				drive-push-pull;
			};

			/omit-if-no-ref/ usart2_de_pa15: usart2_de_pa15 {
				pinmux = <STM32_PINMUX('A', 15, AF3)>;
				drive-push-pull;
			};

			/omit-if-no-ref/ usart2_de_pb1: usart2_de_pb1 {
				pinmux = <STM32_PINMUX('B', 1, AF3)>;
				drive-push-pull;
			};

			/omit-if-no-ref/ usart2_de_pc7: usart2_de_pc7 {
				pinmux = <STM32_PINMUX('C', 7, AF7)>;
				drive-push-pull;
			};

			/omit-if-no-ref/ usart3_de_pa15: usart3_de_pa15 {
				pinmux = <STM32_PINMUX('A', 15, AF7)>;
				drive-push-pull;
			};

			/omit-if-no-ref/ usart3_de_pb1: usart3_de_pb1 {
				pinmux = <STM32_PINMUX('B', 1, AF7)>;
				drive-push-pull;
			};

			/omit-if-no-ref/ usart3_de_pb14: usart3_de_pb14 {
				pinmux = <STM32_PINMUX('B', 14, AF8)>;
				drive-push-pull;
			};

			/* UART_RTS / USART_RTS / LPUART_RTS */

			/omit-if-no-ref/ usart1_rts_pa2: usart1_rts_pa2 {
				pinmux = <STM32_PINMUX('A', 2, AF7)>;
				drive-push-pull;
			};

			/omit-if-no-ref/ usart1_rts_pa3: usart1_rts_pa3 {
				pinmux = <STM32_PINMUX('A', 3, AF7)>;
				drive-push-pull;
			};

			/omit-if-no-ref/ usart1_rts_pa6: usart1_rts_pa6 {
				pinmux = <STM32_PINMUX('A', 6, AF7)>;
				drive-push-pull;
			};

			/omit-if-no-ref/ lpuart1_rts_pa9: lpuart1_rts_pa9 {
				pinmux = <STM32_PINMUX('A', 9, AF8)>;
				drive-push-pull;
			};

			/omit-if-no-ref/ lpuart1_rts_pb9: lpuart1_rts_pb9 {
				pinmux = <STM32_PINMUX('B', 9, AF8)>;
				drive-push-pull;
			};

			/omit-if-no-ref/ usart2_rts_pa15: usart2_rts_pa15 {
				pinmux = <STM32_PINMUX('A', 15, AF3)>;
				drive-push-pull;
			};

			/omit-if-no-ref/ usart2_rts_pb1: usart2_rts_pb1 {
				pinmux = <STM32_PINMUX('B', 1, AF3)>;
				drive-push-pull;
			};

			/omit-if-no-ref/ usart2_rts_pc7: usart2_rts_pc7 {
				pinmux = <STM32_PINMUX('C', 7, AF7)>;
				drive-push-pull;
			};

			/omit-if-no-ref/ usart3_rts_pa15: usart3_rts_pa15 {
				pinmux = <STM32_PINMUX('A', 15, AF7)>;
				drive-push-pull;
			};

			/omit-if-no-ref/ usart3_rts_pb1: usart3_rts_pb1 {
				pinmux = <STM32_PINMUX('B', 1, AF7)>;
				drive-push-pull;
			};

			/omit-if-no-ref/ usart3_rts_pb14: usart3_rts_pb14 {
				pinmux = <STM32_PINMUX('B', 14, AF8)>;
				drive-push-pull;
			};

			/* UART_RX / USART_RX / LPUART_RX */

			/omit-if-no-ref/ lpuart1_rx_pa1: lpuart1_rx_pa1 {
				pinmux = <STM32_PINMUX('A', 1, AF8)>;
			};

			/omit-if-no-ref/ usart1_rx_pa8: usart1_rx_pa8 {
				pinmux = <STM32_PINMUX('A', 8, AF7)>;
			};

			/omit-if-no-ref/ lpuart1_rx_pa10: lpuart1_rx_pa10 {
				pinmux = <STM32_PINMUX('A', 10, AF8)>;
			};

			/omit-if-no-ref/ lpuart1_rx_pc0: lpuart1_rx_pc0 {
				pinmux = <STM32_PINMUX('C', 0, AF8)>;
			};

			/omit-if-no-ref/ usart2_rx_pa11: usart2_rx_pa11 {
				pinmux = <STM32_PINMUX('A', 11, AF3)>;
			};

			/omit-if-no-ref/ usart2_rx_pb4: usart2_rx_pb4 {
				pinmux = <STM32_PINMUX('B', 4, AF3)>;
			};

			/omit-if-no-ref/ usart2_rx_pb8: usart2_rx_pb8 {
				pinmux = <STM32_PINMUX('B', 8, AF3)>;
			};

			/omit-if-no-ref/ usart2_rx_pc8: usart2_rx_pc8 {
				pinmux = <STM32_PINMUX('C', 8, AF7)>;
			};

			/omit-if-no-ref/ usart2_rx_pd5: usart2_rx_pd5 {
				pinmux = <STM32_PINMUX('D', 5, AF7)>;
			};

			/omit-if-no-ref/ usart3_rx_pa5: usart3_rx_pa5 {
				pinmux = <STM32_PINMUX('A', 5, AF8)>;
			};

			/omit-if-no-ref/ usart3_rx_pb11: usart3_rx_pb11 {
				pinmux = <STM32_PINMUX('B', 11, AF7)>;
			};

			/omit-if-no-ref/ usart3_rx_pc5: usart3_rx_pc5 {
				pinmux = <STM32_PINMUX('C', 5, AF7)>;
			};

			/* UART_TX / USART_TX / LPUART_TX */

			/omit-if-no-ref/ lpuart1_tx_pa2: lpuart1_tx_pa2 {
				pinmux = <STM32_PINMUX('A', 2, AF8)>;
				bias-pull-up;
			};

			/omit-if-no-ref/ lpuart1_tx_pb5: lpuart1_tx_pb5 {
				pinmux = <STM32_PINMUX('B', 5, AF8)>;
				bias-pull-up;
			};

			/omit-if-no-ref/ lpuart1_tx_pb11: lpuart1_tx_pb11 {
				pinmux = <STM32_PINMUX('B', 11, AF8)>;
				bias-pull-up;
			};

			/omit-if-no-ref/ usart1_tx_pb12: usart1_tx_pb12 {
				pinmux = <STM32_PINMUX('B', 12, AF7)>;
				bias-pull-up;
			};

			/omit-if-no-ref/ usart1_tx_pb14: usart1_tx_pb14 {
				pinmux = <STM32_PINMUX('B', 14, AF7)>;
				bias-pull-up;
			};

			/omit-if-no-ref/ lpuart1_tx_pc1: lpuart1_tx_pc1 {
				pinmux = <STM32_PINMUX('C', 1, AF8)>;
				bias-pull-up;
			};

			/omit-if-no-ref/ usart2_tx_pa12: usart2_tx_pa12 {
				pinmux = <STM32_PINMUX('A', 12, AF3)>;
				bias-pull-up;
			};

			/omit-if-no-ref/ usart2_tx_pa14: usart2_tx_pa14 {
				pinmux = <STM32_PINMUX('A', 14, AF3)>;
				bias-pull-up;
			};

			/omit-if-no-ref/ usart2_tx_pb0: usart2_tx_pb0 {
				pinmux = <STM32_PINMUX('B', 0, AF3)>;
				bias-pull-up;
			};

			/omit-if-no-ref/ usart2_tx_pd9: usart2_tx_pd9 {
				pinmux = <STM32_PINMUX('D', 9, AF3)>;
				bias-pull-up;
			};

			/omit-if-no-ref/ usart3_tx_pa7: usart3_tx_pa7 {
				pinmux = <STM32_PINMUX('A', 7, AF8)>;
				bias-pull-up;
			};

			/omit-if-no-ref/ usart3_tx_pb10: usart3_tx_pb10 {
				pinmux = <STM32_PINMUX('B', 10, AF8)>;
				bias-pull-up;
			};

			/omit-if-no-ref/ usart3_tx_pc4: usart3_tx_pc4 {
				pinmux = <STM32_PINMUX('C', 4, AF7)>;
				bias-pull-up;
			};

			/omit-if-no-ref/ usart3_tx_pd9: usart3_tx_pd9 {
				pinmux = <STM32_PINMUX('D', 9, AF7)>;
				bias-pull-up;
			};

			/* USB_OTG_HS */

			/omit-if-no-ref/ usb_otg_hs_sof_pa8: usb_otg_hs_sof_pa8 {
				pinmux = <STM32_PINMUX('A', 8, AF10)>;
			};

			/omit-if-no-ref/ usb_otg_hs_sof_pa14: usb_otg_hs_sof_pa14 {
				pinmux = <STM32_PINMUX('A', 14, AF4)>;
			};

			/omit-if-no-ref/ usb_otg_hs_dp_pd6: usb_otg_hs_dp_pd6 {
				pinmux = <STM32_PINMUX('D', 6, ANALOG)>;
			};

			/omit-if-no-ref/ usb_otg_hs_dm_pd7: usb_otg_hs_dm_pd7 {
				pinmux = <STM32_PINMUX('D', 7, ANALOG)>;
			};

			/omit-if-no-ref/ usb_otg_hs_id_pd8: usb_otg_hs_id_pd8 {
				pinmux = <STM32_PINMUX('D', 8, AF10)>;
			};

			/omit-if-no-ref/ usb_otg_hs_vbus_pd9: usb_otg_hs_vbus_pd9 {
				pinmux = <STM32_PINMUX('D', 9, ANALOG)>;
			};

		};
	};
};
